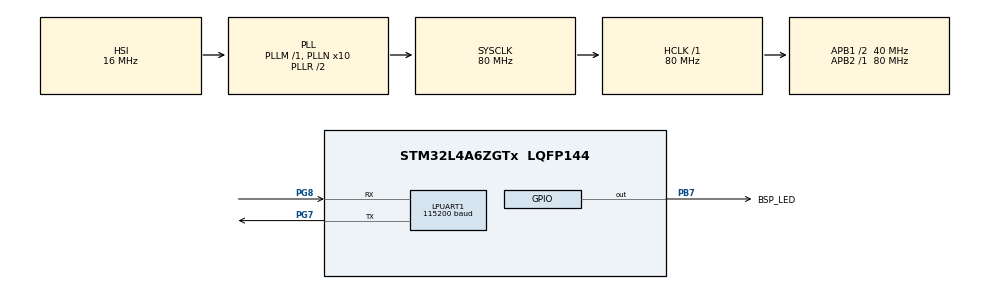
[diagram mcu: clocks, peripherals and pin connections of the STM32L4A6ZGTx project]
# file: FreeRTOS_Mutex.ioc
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FREERTOS.Mutexes01=Mutex_1,Dynamic,NULL
FREERTOS.Tasks01=High_Task,40,128,Start_High_Task,Default,NULL,Dynamic,NULL,NULL;Low_Task,8,128,Start_Low_Task,Default,NULL,Dynamic,NULL,NULL
FREERTOS.configUSE_NEWLIB_REENTRANT=1
LPUART1.BaudRate=115200
LPUART1.WordLength=UART_WORDLENGTH_8B
Mcu.Family=STM32L4
Mcu.Name=STM32L4A6ZGTx
Mcu.Package=LQFP144
NVIC.PriorityGroup=NVIC_PRIORITYGROUP_4
NVIC.TIM6_DAC_IRQn=true\:15\:0\:false\:false\:true\:false\:false\:true\:true
NVIC.TimeBase=TIM6_DAC_IRQn
NVIC.TimeBaseIP=TIM6
PA13\ (JTMS/SWDIO).Mode=Serial_Wire
PA13\ (JTMS/SWDIO).Signal=SYS_JTMS-SWDIO
PA14\ (JTCK/SWCLK).Mode=Serial_Wire
PA14\ (JTCK/SWCLK).Signal=SYS_JTCK-SWCLK
PB7.GPIO_Label=BSP_LED
PB7.Signal=GPIO_Output
PG7.Mode=Asynchronous
PG7.Signal=LPUART1_TX
PG8.Mode=Asynchronous
PG8.Signal=LPUART1_RX
ProjectManager.HeapSize=0x200
ProjectManager.StackSize=0x400
ProjectManager.TargetToolchain=STM32CubeIDE
RCC.ADCFreq_Value=192000000
RCC.AHBFreq_Value=80000000
RCC.APB1CLKDivider=RCC_HCLK_DIV2
RCC.APB1Freq_Value=40000000
RCC.APB1TimFreq_Value=80000000
RCC.APB2Freq_Value=80000000
RCC.APB2TimFreq_Value=80000000
RCC.CortexFreq_Value=80000000
RCC.FLatency=FLASH_LATENCY_4
RCC.HCLKFreq_Value=80000000
RCC.HSE_VALUE=8000000
RCC.HSI48_VALUE=48000000
RCC.HSI_VALUE=16000000
RCC.MSI_VALUE=4000000
RCC.PLLN=10
RCC.PLLSAI1N=24
RCC.PLLSourceVirtual=RCC_PLLSOURCE_HSI
RCC.SYSCLKFreq_VALUE=80000000
RCC.SYSCLKSource=RCC_SYSCLKSOURCE_PLLCLK
RCC.USBFreq_Value=192000000
RCC.VCOOutputFreq_Value=160000000
VP_FREERTOS_VS_CMSIS_V2.Mode=CMSIS_V2
VP_SYS_VS_tim6.Mode=TIM6
board=NUCLEO-L4A6ZG

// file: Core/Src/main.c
/* USER CODE BEGIN Header */
/**
  ******************************************************************************
  * @file           : main.c
  * @brief          : Main program body
  ******************************************************************************
  * @attention
  *
  * Copyright (c) 2024 STMicroelectronics.
  * All rights reserved.
  *
  * This software is licensed under terms that can be found in the LICENSE file
  * in the root directory of this software component.
  * If no LICENSE file comes with this software, it is provided AS-IS.
  *
  ******************************************************************************
  */
/* USER CODE END Header */

/* A mutex in FreeRTOS is like a key that tasks use to access a shared resource,
 * like a printer. Only one task can have the key (mutex) at a time.
 * If a task has the mutex (key), others have to wait until it's done and gives back the mutex.
 * This way, tasks can safely share things like data or devices without causing problems.
 */

/*  Mutexes support priority inheritance. If a high-priority task is waiting for a mutex
 *  held by a low-priority task, the low-priority task inherits(derives) the high-priority task's
 *  priority until it releases the mutex.
 */

#include "main.h"
#include "cmsis_os.h"

/* USER CODE BEGIN Includes */
#include <stdio.h>
/* USER CODE END Includes */

UART_HandleTypeDef hlpuart1;

/* Definitions for High_Task */
osThreadId_t High_TaskHandle;
const osThreadAttr_t High_Task_attributes = {
  .name = "High_Task",
  .stack_size = 128 * 4,
  .priority = (osPriority_t) osPriorityHigh,  // High priority
};
/* Definitions for Low_Task */
osThreadId_t Low_TaskHandle;
const osThreadAttr_t Low_Task_attributes = {
  .name = "Low_Task",
  .stack_size = 128 * 4,
  .priority = (osPriority_t) osPriorityLow,   // Low priority
};
/* Definitions for Mutex_1 */
osMutexId_t Mutex_1Handle;
const osMutexAttr_t Mutex_1_attributes = {
  .name = "Mutex_1"
};

void SystemClock_Config(void);
static void MX_GPIO_Init(void);
static void MX_LPUART1_UART_Init(void);
void Start_High_Task(void *argument);
void Start_Low_Task(void *argument);

int main(void)
{

  /* MCU Configuration--------------------------------------------------------*/

  /* Reset of all peripherals, Initializes the Flash interface and the Systick. */
  HAL_Init();

  /* Configure the system clock */
  SystemClock_Config();

  /* Initialize all configured peripherals */
  MX_GPIO_Init();
  MX_LPUART1_UART_Init();

  /* Init scheduler */
  osKernelInitialize();
  /* Create the mutex(es) */
  /* creation of Mutex_1 */
  Mutex_1Handle = osMutexNew(&Mutex_1_attributes);

  if(Mutex_1Handle == NULL)
  {
	  printf("\r\nFailed to create Mutex\r\n");
  }

  /* Create the thread(s) */
  /* creation of High_Task */
  High_TaskHandle = osThreadNew(Start_High_Task, NULL, &High_Task_attributes);

  /* creation of Low_Task */
  Low_TaskHandle = osThreadNew(Start_Low_Task, NULL, &Low_Task_attributes);

  /* Start scheduler */
  osKernelStart();

  /* Infinite loop */
  while (1)
  {

  }
}

void SystemClock_Config(void)
{
  RCC_OscInitTypeDef RCC_OscInitStruct = {0};
  RCC_ClkInitTypeDef RCC_ClkInitStruct = {0};

  /** Configure the main internal regulator output voltage
  */
  if (HAL_PWREx_ControlVoltageScaling(PWR_REGULATOR_VOLTAGE_SCALE1) != HAL_OK)
  {
    Error_Handler();
  }

  /** Initializes the RCC Oscillators according to the specified parameters
  * in the RCC_OscInitTypeDef structure.
  */
  RCC_OscInitStruct.OscillatorType = RCC_OSCILLATORTYPE_HSI;
  RCC_OscInitStruct.HSIState = RCC_HSI_ON;
  RCC_OscInitStruct.HSICalibrationValue = RCC_HSICALIBRATION_DEFAULT;
  RCC_OscInitStruct.PLL.PLLState = RCC_PLL_ON;
  RCC_OscInitStruct.PLL.PLLSource = RCC_PLLSOURCE_HSI;
  RCC_OscInitStruct.PLL.PLLM = 1;
  RCC_OscInitStruct.PLL.PLLN = 10;
  RCC_OscInitStruct.PLL.PLLP = RCC_PLLP_DIV2;
  RCC_OscInitStruct.PLL.PLLQ = RCC_PLLQ_DIV2;
  RCC_OscInitStruct.PLL.PLLR = RCC_PLLR_DIV2;
  if (HAL_RCC_OscConfig(&RCC_OscInitStruct) != HAL_OK)
  {
    Error_Handler();
  }

  /** Initializes the CPU, AHB and APB buses clocks
  */
  RCC_ClkInitStruct.ClockType = RCC_CLOCKTYPE_HCLK|RCC_CLOCKTYPE_SYSCLK
                              |RCC_CLOCKTYPE_PCLK1|RCC_CLOCKTYPE_PCLK2;
  RCC_ClkInitStruct.SYSCLKSource = RCC_SYSCLKSOURCE_PLLCLK;
  RCC_ClkInitStruct.AHBCLKDivider = RCC_SYSCLK_DIV1;
  RCC_ClkInitStruct.APB1CLKDivider = RCC_HCLK_DIV2;
  RCC_ClkInitStruct.APB2CLKDivider = RCC_HCLK_DIV1;

  if (HAL_RCC_ClockConfig(&RCC_ClkInitStruct, FLASH_LATENCY_4) != HAL_OK)
  {
    Error_Handler();
  }
}

static void MX_LPUART1_UART_Init(void)
{
  hlpuart1.Instance = LPUART1;
  hlpuart1.Init.BaudRate = 115200;
  hlpuart1.Init.WordLength = UART_WORDLENGTH_8B;
  hlpuart1.Init.StopBits = UART_STOPBITS_1;
  hlpuart1.Init.Parity = UART_PARITY_NONE;
  hlpuart1.Init.Mode = UART_MODE_TX_RX;
  hlpuart1.Init.HwFlowCtl = UART_HWCONTROL_NONE;
  hlpuart1.Init.OneBitSampling = UART_ONE_BIT_SAMPLE_DISABLE;
  hlpuart1.AdvancedInit.AdvFeatureInit = UART_ADVFEATURE_NO_INIT;
  if (HAL_UART_Init(&hlpuart1) != HAL_OK)
  {
    Error_Handler();
  }
}

static void MX_GPIO_Init(void)
{
  GPIO_InitTypeDef GPIO_InitStruct = {0};

  /* GPIO Ports Clock Enable */
  __HAL_RCC_GPIOG_CLK_ENABLE();
  HAL_PWREx_EnableVddIO2();
  __HAL_RCC_GPIOA_CLK_ENABLE();
  __HAL_RCC_GPIOB_CLK_ENABLE();

  /*Configure GPIO pin Output Level */
  HAL_GPIO_WritePin(BSP_LED_GPIO_Port, BSP_LED_Pin, GPIO_PIN_RESET);

  /*Configure GPIO pin : BSP_LED_Pin */
  GPIO_InitStruct.Pin = BSP_LED_Pin;
  GPIO_InitStruct.Mode = GPIO_MODE_OUTPUT_PP;
  GPIO_InitStruct.Pull = GPIO_NOPULL;
  GPIO_InitStruct.Speed = GPIO_SPEED_FREQ_LOW;
  HAL_GPIO_Init(BSP_LED_GPIO_Port, &GPIO_InitStruct);
}

void Start_High_Task(void *argument)
{
  /* USER CODE BEGIN 5 */
  /* Infinite loop */
  for(;;)
  {
    if(osMutexAcquire(Mutex_1Handle, osWaitForever) == osOK)
    {
      printf("\r\nHigh Priority Task: Mutex acquired\r\n");
      HAL_GPIO_WritePin(GPIOB, GPIO_PIN_7, GPIO_PIN_SET); // Turn on the LED

      osDelay(1000);  // Simulate some work

      printf("High Priority Task: Mutex released\r\n");
      osMutexRelease(Mutex_1Handle);
    }
    osDelay(1000);  // Wait before next attempt to acquire the mutex
  }
  /* USER CODE END 5 */
}

void Start_Low_Task(void *argument)
{
  /* USER CODE BEGIN Start_Low_Task */
  /* Infinite loop */
  for(;;)
  {
    if(osMutexAcquire(Mutex_1Handle, osWaitForever) == osOK)
    {
      printf("\r\nLow Priority Task: Mutex acquired\r\n");
      HAL_GPIO_WritePin(GPIOB, GPIO_PIN_7, GPIO_PIN_RESET); // Turn off the LED

      osDelay(1000);  // Simulate some work

      printf("Low Priority Task: Mutex released\r\n");
      osMutexRelease(Mutex_1Handle);
    }
    osDelay(1000);  // Wait before next attempt to acquire the mutex
  }
  /* USER CODE END Start_Low_Task */
}

void Error_Handler(void)
{
  /* USER CODE BEGIN Error_Handler_Debug */
  /* User can add their own implementation to report the HAL error return state */
  __disable_irq();
  while (1)
  {
  }
  /* USER CODE END Error_Handler_Debug */
}

#ifdef  USE_FULL_ASSERT
/**
  * @brief  Reports the name of the source file and the source line number
  *         where the assert_param error has occurred.
  * @param  file: pointer to the source file name
  * @param  line: assert_param error line source number
  * @retval None
  */
void assert_failed(uint8_t *file, uint32_t line)
{
  /* USER CODE BEGIN 6 */
  /* User can add their own implementation to report the file name and line number,
     ex: printf("Wrong parameters value: file %s on line %d\r\n", file, line) */
  /* USER CODE END 6 */
}
#endif /* USE_FULL_ASSERT */
